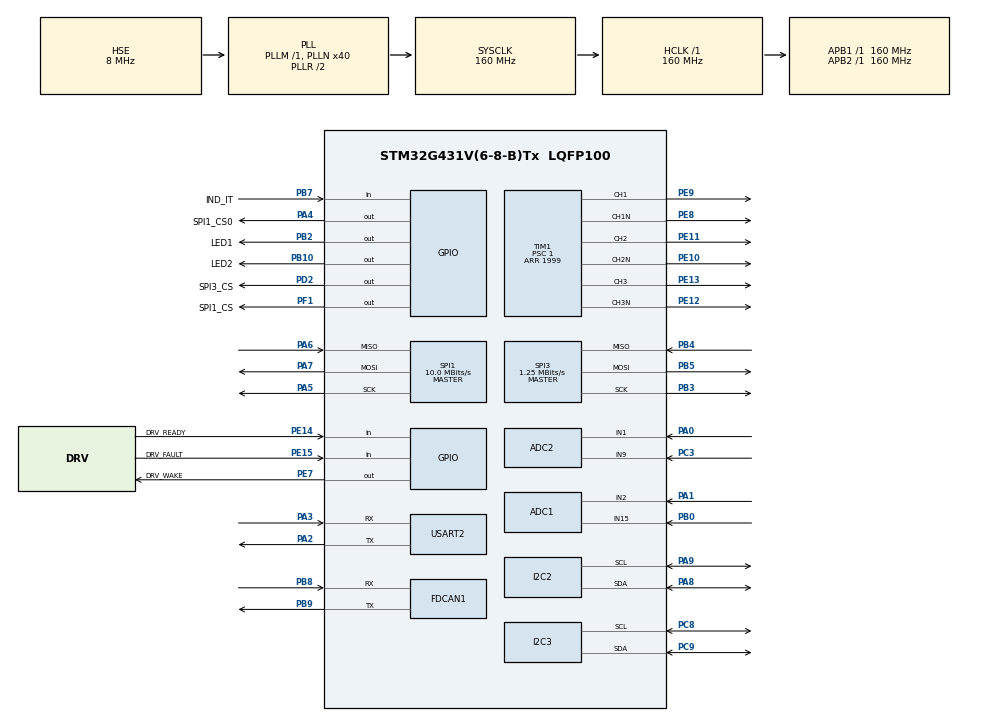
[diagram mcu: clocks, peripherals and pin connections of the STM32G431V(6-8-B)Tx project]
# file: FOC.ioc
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ADC1.Channel-0\#ChannelRegularConversion=ADC_CHANNEL_2
ADC1.Channel-3\#ChannelRegularConversion=ADC_CHANNEL_15
ADC1.Channel-4\#ChannelRegularConversion=ADC_CHANNEL_TEMPSENSOR_ADC1
ADC1.ClockPrescaler=ADC_CLOCK_SYNC_PCLK_DIV4
ADC1.ContinuousConvMode=DISABLE
ADC1.DMAContinuousRequests=ENABLE
ADC1.EOCSelection=ADC_EOC_SEQ_CONV
ADC1.ExternalTrigConv=ADC_EXTERNALTRIG_T1_TRGO
ADC1.NbrOfConversion=3
ADC1.NbrOfConversionFlag=1
ADC1.OffsetNumber-0\#ChannelRegularConversion=ADC_OFFSET_NONE
ADC1.OffsetNumber-3\#ChannelRegularConversion=ADC_OFFSET_NONE
ADC1.OffsetNumber-4\#ChannelRegularConversion=ADC_OFFSET_NONE
ADC1.Overrun=ADC_OVR_DATA_OVERWRITTEN
ADC1.OversamplingMode=DISABLE
ADC1.Rank-0\#ChannelRegularConversion=1
ADC1.Rank-3\#ChannelRegularConversion=2
ADC1.Rank-4\#ChannelRegularConversion=3
ADC1.SamplingTime-0\#ChannelRegularConversion=ADC_SAMPLETIME_92CYCLES_5
ADC1.SamplingTime-3\#ChannelRegularConversion=ADC_SAMPLETIME_92CYCLES_5
ADC1.SamplingTime-4\#ChannelRegularConversion=ADC_SAMPLETIME_640CYCLES_5
ADC1.master=1
ADC2.Channel-0\#ChannelRegularConversion=ADC_CHANNEL_1
ADC2.Channel-1\#ChannelRegularConversion=ADC_CHANNEL_9
ADC2.ContinuousConvMode=DISABLE
ADC2.DMAContinuousRequests=ENABLE
ADC2.EOCSelection=ADC_EOC_SEQ_CONV
ADC2.ExternalTrigConv=ADC_EXTERNALTRIG_T1_TRGO
ADC2.NbrOfConversion=2
ADC2.NbrOfConversionFlag=1
ADC2.OffsetNumber-0\#ChannelRegularConversion=ADC_OFFSET_NONE
ADC2.OffsetNumber-1\#ChannelRegularConversion=ADC_OFFSET_NONE
ADC2.Overrun=ADC_OVR_DATA_OVERWRITTEN
ADC2.Rank-0\#ChannelRegularConversion=1
ADC2.Rank-1\#ChannelRegularConversion=2
ADC2.SamplingTime-0\#ChannelRegularConversion=ADC_SAMPLETIME_92CYCLES_5
ADC2.SamplingTime-1\#ChannelRegularConversion=ADC_SAMPLETIME_640CYCLES_5
Dma.ADC1.0.Direction=DMA_PERIPH_TO_MEMORY
Dma.ADC1.0.EventEnable=DISABLE
Dma.ADC1.0.Instance=DMA1_Channel1
Dma.ADC1.0.MemDataAlignment=DMA_MDATAALIGN_WORD
Dma.ADC1.0.MemInc=DMA_MINC_ENABLE
Dma.ADC1.0.Mode=DMA_CIRCULAR
Dma.ADC1.0.PeriphDataAlignment=DMA_PDATAALIGN_WORD
Dma.ADC1.0.PeriphInc=DMA_PINC_DISABLE
Dma.ADC1.0.Polarity=HAL_DMAMUX_REQ_GEN_RISING
Dma.ADC1.0.Priority=DMA_PRIORITY_HIGH
Dma.ADC1.0.RequestNumber=1
Dma.ADC1.0.SignalID=NONE
Dma.ADC1.0.SyncEnable=DISABLE
Dma.ADC1.0.SyncPolarity=HAL_DMAMUX_SYNC_NO_EVENT
Dma.ADC1.0.SyncRequestNumber=1
Dma.ADC1.0.SyncSignalID=NONE
Dma.ADC2.1.Direction=DMA_PERIPH_TO_MEMORY
Dma.ADC2.1.EventEnable=DISABLE
Dma.ADC2.1.Instance=DMA1_Channel2
Dma.ADC2.1.MemDataAlignment=DMA_MDATAALIGN_WORD
Dma.ADC2.1.MemInc=DMA_MINC_ENABLE
Dma.ADC2.1.Mode=DMA_CIRCULAR
Dma.ADC2.1.PeriphDataAlignment=DMA_PDATAALIGN_WORD
Dma.ADC2.1.PeriphInc=DMA_PINC_DISABLE
Dma.ADC2.1.Polarity=HAL_DMAMUX_REQ_GEN_RISING
Dma.ADC2.1.Priority=DMA_PRIORITY_HIGH
Dma.ADC2.1.RequestNumber=1
Dma.ADC2.1.SignalID=NONE
Dma.ADC2.1.SyncEnable=DISABLE
Dma.ADC2.1.SyncPolarity=HAL_DMAMUX_SYNC_NO_EVENT
Dma.ADC2.1.SyncRequestNumber=1
Dma.ADC2.1.SyncSignalID=NONE
Dma.Request0=ADC1
Dma.Request1=ADC2
FDCAN1.AutoRetransmission=ENABLE
FDCAN1.CalculateBaudRateNominal=1000000
FDCAN1.CalculateTimeBitNominal=1000
FDCAN1.CalculateTimeQuantumNominal=12.5
FDCAN1.ClockDivider=FDCAN_CLOCK_DIV2
FDCAN1.DataSyncJumpWidth=4
FDCAN1.DataTimeSeg1=5
FDCAN1.DataTimeSeg2=4
FDCAN1.ExtFiltersNbr=1
FDCAN1.FrameFormat=FDCAN_FRAME_FD_BRS
FDCAN1.NominalPrescaler=1
FDCAN1.NominalSyncJumpWidth=24
FDCAN1.NominalTimeSeg1=55
FDCAN1.NominalTimeSeg2=24
I2C2.Timing=0x30D29DE4
I2C3.Speed=100
I2C3.Timing=0x30D29DE4
Mcu.Family=STM32G4
Mcu.Name=STM32G431V(6-8-B)Tx
Mcu.Package=LQFP100
NVIC.DMA1_Channel1_IRQn=true\:0\:0\:false\:false\:true\:false\:true\:true
NVIC.DMA1_Channel2_IRQn=true\:0\:0\:false\:false\:true\:false\:true\:true
NVIC.FDCAN1_IT0_IRQn=true\:2\:0\:true\:false\:true\:true\:true\:true
NVIC.PriorityGroup=NVIC_PRIORITYGROUP_4
NVIC.TIM1_UP_TIM16_IRQn=true\:1\:0\:true\:false\:true\:true\:true\:true
NVIC.TIM7_IRQn=true\:0\:0\:false\:false\:true\:true\:true\:true
PA0.Mode=IN1-Single-Ended
PA0.Signal=ADC2_IN1
PA1.Mode=IN2-Single-Ended
PA1.Signal=ADC1_IN2
PA13.Mode=Serial_Wire
PA13.Signal=SYS_JTMS-SWDIO
PA14.Mode=Serial_Wire
PA14.Signal=SYS_JTCK-SWCLK
PA2.Mode=Asynchronous
PA2.Signal=USART2_TX
PA3.Mode=Asynchronous
PA3.Signal=USART2_RX
PA4.GPIO_Label=SPI1_CS0
PA4.Signal=GPIO_Output
PA5.GPIO_Speed=GPIO_SPEED_FREQ_MEDIUM
PA5.Mode=Full_Duplex_Master
PA5.Signal=SPI1_SCK
PA6.GPIO_Speed=GPIO_SPEED_FREQ_MEDIUM
PA6.Mode=Full_Duplex_Master
PA6.Signal=SPI1_MISO
PA7.GPIO_Speed=GPIO_SPEED_FREQ_MEDIUM
PA7.Mode=Full_Duplex_Master
PA7.Signal=SPI1_MOSI
PA8.GPIO_Pu=GPIO_PULLUP
PA8.Mode=I2C
PA8.Signal=I2C2_SDA
PA9.GPIO_Pu=GPIO_PULLUP
PA9.Mode=I2C
PA9.Signal=I2C2_SCL
PB0.Mode=IN15-Single-Ended
PB0.Signal=ADC1_IN15
PB10.GPIO_Label=LED2
PB10.GPIO_ModeDefaultOutputPP=GPIO_MODE_OUTPUT_OD
PB10.GPIO_PuPd=GPIO_NOPULL
PB10.Signal=GPIO_Output
PB2.GPIO_Label=LED1
PB2.GPIO_ModeDefaultOutputPP=GPIO_MODE_OUTPUT_OD
PB2.GPIO_PuPd=GPIO_NOPULL
PB2.Signal=GPIO_Output
PB3.GPIO_PuPd=GPIO_PULLDOWN
PB3.GPIO_Speed=GPIO_SPEED_FREQ_LOW
PB3.Mode=Full_Duplex_Master
PB3.Signal=SPI3_SCK
PB4.GPIO_PuPd=GPIO_PULLDOWN
PB4.GPIO_Speed=GPIO_SPEED_FREQ_LOW
PB4.Mode=Full_Duplex_Master
PB4.Signal=SPI3_MISO
PB5.GPIO_PuPd=GPIO_PULLDOWN
PB5.GPIO_Speed=GPIO_SPEED_FREQ_LOW
PB5.Mode=Full_Duplex_Master
PB5.Signal=SPI3_MOSI
PB7.GPIO_Label=IND_IT
PB7.Signal=GPIO_Input
PB8-BOOT0.Mode=FDCAN_Activate
PB8-BOOT0.Signal=FDCAN1_RX
PB9.Mode=FDCAN_Activate
PB9.Signal=FDCAN1_TX
PC3.Mode=IN9-Single-Ended
PC3.Signal=ADC2_IN9
PC8.GPIO_Pu=GPIO_NOPULL
PC8.Mode=I2C
PC8.Signal=I2C3_SCL
PC9.GPIO_Pu=GPIO_NOPULL
PC9.Mode=I2C
PC9.Signal=I2C3_SDA
PD2.GPIO_Label=SPI3_CS
PD2.Signal=GPIO_Output
PE10.Mode=PWM Generation2 CH2 CH2N
PE10.Signal=TIM1_CH2N
PE11.Signal=S_TIM1_CH2
PE12.Mode=PWM Generation3 CH3 CH3N
PE12.Signal=TIM1_CH3N
PE13.Signal=S_TIM1_CH3
PE14.GPIO_Label=DRV_READY
PE14.GPIO_PuPd=GPIO_PULLUP
PE14.Signal=GPIO_Input
PE15.GPIO_Label=DRV_FAULT
PE15.GPIO_PuPd=GPIO_PULLUP
PE15.Signal=GPIO_Input
PE7.GPIO_Label=DRV_WAKE
PE7.Signal=GPIO_Output
PE8.Mode=PWM Generation1 CH1 CH1N
PE8.Signal=TIM1_CH1N
PE9.Signal=S_TIM1_CH1
PF0-OSC_IN.Mode=HSE-External-Clock-Source
PF0-OSC_IN.Signal=RCC_OSC_IN
PF1-OSC_OUT.GPIO_Label=SPI1_CS
PF1-OSC_OUT.Signal=GPIO_Output
ProjectManager.HeapSize=0x2000
ProjectManager.StackSize=0x4000
ProjectManager.TargetToolchain=CMake
RCC.ADC12Freq_Value=160000000
RCC.ADC345Freq_Value=160000000
RCC.AHBFreq_Value=160000000
RCC.APB1Freq_Value=160000000
RCC.APB1TimFreq_Value=160000000
RCC.APB2Freq_Value=160000000
RCC.APB2TimFreq_Value=160000000
RCC.CortexFreq_Value=160000000
RCC.EXTERNAL_CLOCK_VALUE=12288000
RCC.HCLKFreq_Value=160000000
RCC.HSE_VALUE=8000000
RCC.HSI48_VALUE=48000000
RCC.HSI_VALUE=16000000
RCC.LSE_VALUE=32768
RCC.PLLN=40
RCC.PLLSourceVirtual=RCC_PLLSOURCE_HSE
RCC.SYSCLKFreq_VALUE=160000000
RCC.SYSCLKSource=RCC_SYSCLKSOURCE_PLLCLK
RCC.USBFreq_Value=160000000
RCC.VCOOutputFreq_Value=320000000
SH.S_TIM1_CH1.0=TIM1_CH1,PWM Generation1 CH1 CH1N
SH.S_TIM1_CH2.0=TIM1_CH2,PWM Generation2 CH2 CH2N
SH.S_TIM1_CH3.0=TIM1_CH3,PWM Generation3 CH3 CH3N
SPI1.BaudRatePrescaler=SPI_BAUDRATEPRESCALER_16
SPI1.CLKPhase=SPI_PHASE_2EDGE
SPI1.CalculateBaudRate=10.0 MBits/s
SPI1.DataSize=SPI_DATASIZE_16BIT
SPI1.Direction=SPI_DIRECTION_2LINES
SPI1.Mode=SPI_MODE_MASTER
SPI1.VirtualType=VM_MASTER
SPI3.BaudRatePrescaler=SPI_BAUDRATEPRESCALER_128
SPI3.CLKPhase=SPI_PHASE_1EDGE
SPI3.CRCCalculation=SPI_CRCCALCULATION_DISABLE
SPI3.CalculateBaudRate=1.25 MBits/s
SPI3.DataSize=SPI_DATASIZE_16BIT
SPI3.Direction=SPI_DIRECTION_2LINES
SPI3.Mode=SPI_MODE_MASTER
SPI3.NSSPMode=SPI_NSS_PULSE_DISABLE
SPI3.VirtualType=VM_MASTER
TIM1.Channel-PWM\ Generation1\ CH1\ CH1N=TIM_CHANNEL_1
TIM1.Channel-PWM\ Generation2\ CH2\ CH2N=TIM_CHANNEL_2
TIM1.Channel-PWM\ Generation3\ CH3\ CH3N=TIM_CHANNEL_3
TIM1.CounterMode=TIM_COUNTERMODE_DOWN
TIM1.PeriodNoDither=1999
TIM1.Prescaler=1
TIM1.TIM_MasterOutputTrigger=TIM_TRGO_UPDATE
TIM7.PeriodNoDither=50000
TIM7.Prescaler=160
USART2.VirtualMode-Asynchronous=VM_ASYNC
VP_ADC1_TempSens_Input.Mode=IN-TempSens
VP_CORDIC_VS_CORDIC.Mode=CORDIC_Activate
VP_SYS_VS_DBSignals.Mode=DisableDeadBatterySignals
VP_TIM7_VS_ClockSourceINT.Mode=Enable_Timer
board=custom

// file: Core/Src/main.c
/* USER CODE BEGIN Header */
/**
  ******************************************************************************
  * @file           : main.c
  * @brief          : Main program body
  ******************************************************************************
  * @attention
  *
  * Copyright (c) 2025 STMicroelectronics.
  * All rights reserved.
  *
  * This software is licensed under terms that can be found in the LICENSE file
  * in the root directory of this software component.
  * If no LICENSE file comes with this software, it is provided AS-IS.
  *
  ******************************************************************************
  */
/* USER CODE END Header */
#include "main.h"
#include "adc.h"
#include "cordic.h"
#include "dma.h"
#include "fdcan.h"
#include "i2c.h"
#include "spi.h"
#include "tim.h"
#include "usart.h"
#include "gpio.h"

/* USER CODE BEGIN Includes */
#include "AS5147.h"
#include "arm_math.h"
//#include "my_helpers.h"
//#include "communication.h"

//#include "Transform.h"
//#include "math_ops.h"

//#include "eeprom.h"
/* USER CODE END Includes */

void SystemClock_Config(void);

int main(void)
{

  /* MCU Configuration--------------------------------------------------------*/

  /* Reset of all peripherals, Initializes the Flash interface and the Systick. */
  HAL_Init();

  /* Configure the system clock */
  SystemClock_Config();

  /* Initialize all configured peripherals */
  MX_GPIO_Init();
  MX_DMA_Init();
  MX_ADC1_Init();
  MX_SPI3_Init();
  MX_CORDIC_Init();
  MX_TIM1_Init();
  MX_I2C3_Init();
  MX_FDCAN1_Init();
  MX_TIM7_Init();
  MX_ADC2_Init();
  MX_I2C2_Init();
  MX_SPI1_Init();
  MX_USART2_UART_Init();
  /* USER CODE BEGIN 2 */
  HAL_TIM_Base_Start_IT(&htim7);

  app();
  /* USER CODE END 2 */

  /* Infinite loop */
  while (1)
  {

  }
}

void SystemClock_Config(void)
{
  RCC_OscInitTypeDef RCC_OscInitStruct = {0};
  RCC_ClkInitTypeDef RCC_ClkInitStruct = {0};

  /** Configure the main internal regulator output voltage
  */
  HAL_PWREx_ControlVoltageScaling(PWR_REGULATOR_VOLTAGE_SCALE1_BOOST);

  /** Initializes the RCC Oscillators according to the specified parameters
  * in the RCC_OscInitTypeDef structure.
  */
  RCC_OscInitStruct.OscillatorType = RCC_OSCILLATORTYPE_HSE;
  RCC_OscInitStruct.HSEState = RCC_HSE_BYPASS;
  RCC_OscInitStruct.PLL.PLLState = RCC_PLL_ON;
  RCC_OscInitStruct.PLL.PLLSource = RCC_PLLSOURCE_HSE;
  RCC_OscInitStruct.PLL.PLLM = RCC_PLLM_DIV1;
  RCC_OscInitStruct.PLL.PLLN = 40;
  RCC_OscInitStruct.PLL.PLLP = RCC_PLLP_DIV2;
  RCC_OscInitStruct.PLL.PLLQ = RCC_PLLQ_DIV2;
  RCC_OscInitStruct.PLL.PLLR = RCC_PLLR_DIV2;
  if (HAL_RCC_OscConfig(&RCC_OscInitStruct) != HAL_OK)
  {
    Error_Handler();
  }

  /** Initializes the CPU, AHB and APB buses clocks
  */
  RCC_ClkInitStruct.ClockType = RCC_CLOCKTYPE_HCLK|RCC_CLOCKTYPE_SYSCLK
                              |RCC_CLOCKTYPE_PCLK1|RCC_CLOCKTYPE_PCLK2;
  RCC_ClkInitStruct.SYSCLKSource = RCC_SYSCLKSOURCE_PLLCLK;
  RCC_ClkInitStruct.AHBCLKDivider = RCC_SYSCLK_DIV1;
  RCC_ClkInitStruct.APB1CLKDivider = RCC_HCLK_DIV1;
  RCC_ClkInitStruct.APB2CLKDivider = RCC_HCLK_DIV1;

  if (HAL_RCC_ClockConfig(&RCC_ClkInitStruct, FLASH_LATENCY_4) != HAL_OK)
  {
    Error_Handler();
  }
}

void Error_Handler(void)
{
  __disable_irq();
  while (1)
  {
  }
}
